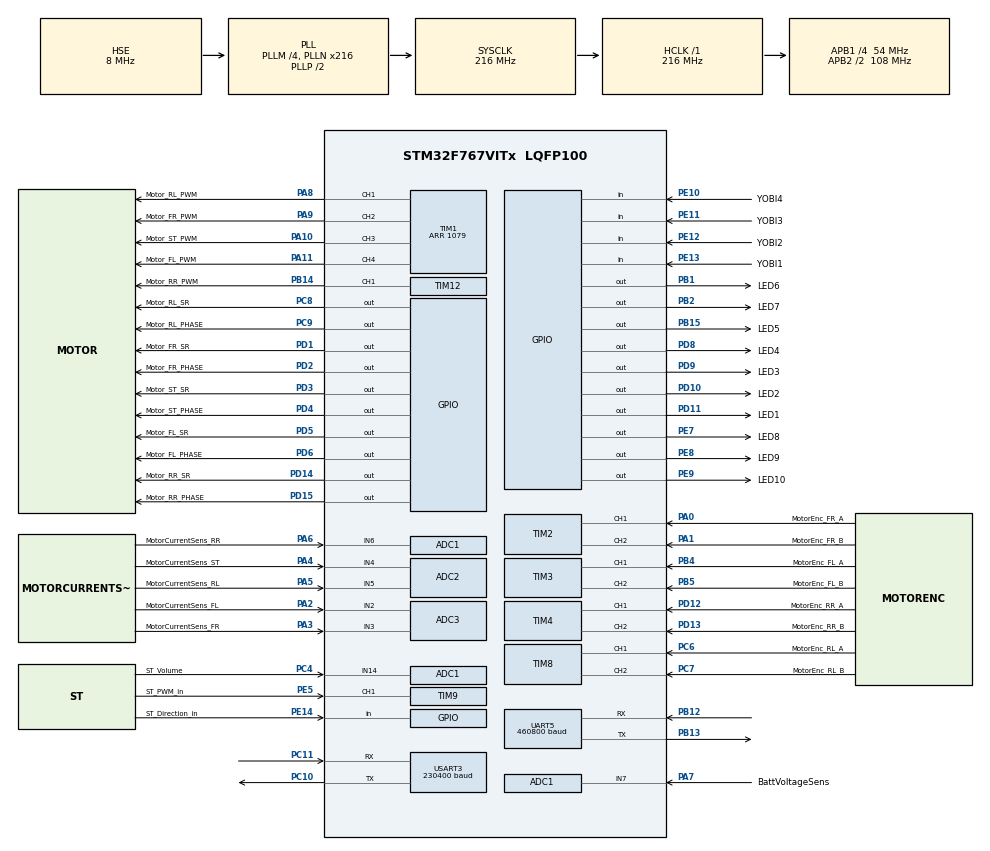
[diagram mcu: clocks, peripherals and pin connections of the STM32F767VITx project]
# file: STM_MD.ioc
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ADC1.Channel-1\#ChannelRegularConversion=ADC_CHANNEL_7
ADC1.Channel-2\#ChannelRegularConversion=ADC_CHANNEL_14
ADC1.Channel-3\#ChannelInjectedConversion=ADC_CHANNEL_6
ADC1.ContinuousConvMode=ENABLE
ADC1.DMAContinuousRequests=ENABLE
ADC1.DiscontinuousConvMode=DISABLE
ADC1.EnableAnalogWatchDog=false
ADC1.ExternalTrigInjecConv=ADC_EXTERNALTRIGINJECCONV_T1_TRGO
ADC1.InjNumberOfConversion=1
ADC1.InjectedOffset-3\#ChannelInjectedConversion=0
ADC1.InjectedRank-3\#ChannelInjectedConversion=1
ADC1.NbrOfConversion=2
ADC1.NbrOfConversionFlag=1
ADC1.Rank-1\#ChannelRegularConversion=1
ADC1.Rank-2\#ChannelRegularConversion=2
ADC1.SamplingTime-1\#ChannelRegularConversion=ADC_SAMPLETIME_3CYCLES
ADC1.SamplingTime-2\#ChannelRegularConversion=ADC_SAMPLETIME_3CYCLES
ADC1.SamplingTime-3\#ChannelInjectedConversion=ADC_SAMPLETIME_480CYCLES
ADC1.ScanConvMode=ADC_SCAN_ENABLE
ADC1.master=1
ADC2.Channel-0\#ChannelRegularConversion=ADC_CHANNEL_4
ADC2.Channel-3\#ChannelInjectedConversion=ADC_CHANNEL_4
ADC2.Channel-4\#ChannelInjectedConversion=ADC_CHANNEL_5
ADC2.ContinuousConvMode=ENABLE
ADC2.DMAContinuousRequests=ENABLE
ADC2.ExternalTrigInjecConv=ADC_EXTERNALTRIGINJECCONV_T1_TRGO
ADC2.InjNumberOfConversion=2
ADC2.InjectedOffset-3\#ChannelInjectedConversion=0
ADC2.InjectedOffset-4\#ChannelInjectedConversion=0
ADC2.InjectedRank-3\#ChannelInjectedConversion=1
ADC2.InjectedRank-4\#ChannelInjectedConversion=2
ADC2.NbrOfConversion=1
ADC2.NbrOfConversionFlag=1
ADC2.Rank-0\#ChannelRegularConversion=1
ADC2.SamplingTime-0\#ChannelRegularConversion=ADC_SAMPLETIME_84CYCLES
ADC2.SamplingTime-3\#ChannelInjectedConversion=ADC_SAMPLETIME_3CYCLES
ADC2.SamplingTime-4\#ChannelInjectedConversion=ADC_SAMPLETIME_3CYCLES
ADC2.ScanConvMode=ADC_SCAN_ENABLE
ADC3.Channel-0\#ChannelRegularConversion=ADC_CHANNEL_2
ADC3.Channel-1\#ChannelRegularConversion=ADC_CHANNEL_3
ADC3.Channel-2\#ChannelInjectedConversion=ADC_CHANNEL_2
ADC3.Channel-3\#ChannelInjectedConversion=ADC_CHANNEL_3
ADC3.ClockPrescaler=ADC_CLOCK_SYNC_PCLK_DIV4
ADC3.ContinuousConvMode=ENABLE
ADC3.DMAContinuousRequests=ENABLE
ADC3.ExternalTrigInjecConv=ADC_EXTERNALTRIGINJECCONV_T1_TRGO
ADC3.InjNumberOfConversion=2
ADC3.InjectedOffset-2\#ChannelInjectedConversion=0
ADC3.InjectedOffset-3\#ChannelInjectedConversion=0
ADC3.InjectedRank-2\#ChannelInjectedConversion=1
ADC3.InjectedRank-3\#ChannelInjectedConversion=2
ADC3.NbrOfConversion=2
ADC3.NbrOfConversionFlag=1
ADC3.Rank-0\#ChannelRegularConversion=1
ADC3.Rank-1\#ChannelRegularConversion=2
ADC3.SamplingTime-0\#ChannelRegularConversion=ADC_SAMPLETIME_112CYCLES
ADC3.SamplingTime-1\#ChannelRegularConversion=ADC_SAMPLETIME_112CYCLES
ADC3.SamplingTime-2\#ChannelInjectedConversion=ADC_SAMPLETIME_3CYCLES
ADC3.SamplingTime-3\#ChannelInjectedConversion=ADC_SAMPLETIME_3CYCLES
ADC3.ScanConvMode=ADC_SCAN_ENABLE
CORTEX_M7.ART_ACCELERATOR_ENABLE=1
CORTEX_M7.CPU_DCache=Enabled
CORTEX_M7.CPU_ICache=Enabled
CORTEX_M7.FlashInterface=TCM_Enabled
CORTEX_M7.PREFETCH_ENABLE=1
CORTEX_M7.default_mode_Activation=0
Dma.ADC1.0.Direction=DMA_PERIPH_TO_MEMORY
Dma.ADC1.0.FIFOMode=DMA_FIFOMODE_DISABLE
Dma.ADC1.0.Instance=DMA2_Stream0
Dma.ADC1.0.MemDataAlignment=DMA_MDATAALIGN_HALFWORD
Dma.ADC1.0.MemInc=DMA_MINC_ENABLE
Dma.ADC1.0.Mode=DMA_CIRCULAR
Dma.ADC1.0.PeriphDataAlignment=DMA_PDATAALIGN_HALFWORD
Dma.ADC1.0.PeriphInc=DMA_PINC_DISABLE
Dma.ADC1.0.Priority=DMA_PRIORITY_LOW
Dma.ADC2.3.Direction=DMA_PERIPH_TO_MEMORY
Dma.ADC2.3.FIFOMode=DMA_FIFOMODE_DISABLE
Dma.ADC2.3.Instance=DMA2_Stream2
Dma.ADC2.3.MemDataAlignment=DMA_MDATAALIGN_HALFWORD
Dma.ADC2.3.MemInc=DMA_MINC_ENABLE
Dma.ADC2.3.Mode=DMA_CIRCULAR
Dma.ADC2.3.PeriphDataAlignment=DMA_PDATAALIGN_HALFWORD
Dma.ADC2.3.PeriphInc=DMA_PINC_DISABLE
Dma.ADC2.3.Priority=DMA_PRIORITY_LOW
Dma.ADC3.4.Direction=DMA_PERIPH_TO_MEMORY
Dma.ADC3.4.FIFOMode=DMA_FIFOMODE_DISABLE
Dma.ADC3.4.Instance=DMA2_Stream1
Dma.ADC3.4.MemDataAlignment=DMA_MDATAALIGN_HALFWORD
Dma.ADC3.4.MemInc=DMA_MINC_ENABLE
Dma.ADC3.4.Mode=DMA_CIRCULAR
Dma.ADC3.4.PeriphDataAlignment=DMA_PDATAALIGN_HALFWORD
Dma.ADC3.4.PeriphInc=DMA_PINC_DISABLE
Dma.ADC3.4.Priority=DMA_PRIORITY_LOW
Dma.Request0=ADC1
Dma.Request1=UART5_RX
Dma.Request2=UART5_TX
Dma.Request3=ADC2
Dma.Request4=ADC3
Dma.UART5_RX.1.Direction=DMA_PERIPH_TO_MEMORY
Dma.UART5_RX.1.FIFOMode=DMA_FIFOMODE_DISABLE
Dma.UART5_RX.1.Instance=DMA1_Stream0
Dma.UART5_RX.1.MemDataAlignment=DMA_MDATAALIGN_BYTE
Dma.UART5_RX.1.MemInc=DMA_MINC_ENABLE
Dma.UART5_RX.1.Mode=DMA_CIRCULAR
Dma.UART5_RX.1.PeriphDataAlignment=DMA_PDATAALIGN_BYTE
Dma.UART5_RX.1.PeriphInc=DMA_PINC_DISABLE
Dma.UART5_RX.1.Priority=DMA_PRIORITY_LOW
Dma.UART5_TX.2.Direction=DMA_MEMORY_TO_PERIPH
Dma.UART5_TX.2.FIFOMode=DMA_FIFOMODE_DISABLE
Dma.UART5_TX.2.Instance=DMA1_Stream7
Dma.UART5_TX.2.MemDataAlignment=DMA_MDATAALIGN_BYTE
Dma.UART5_TX.2.MemInc=DMA_MINC_ENABLE
Dma.UART5_TX.2.Mode=DMA_NORMAL
Dma.UART5_TX.2.PeriphDataAlignment=DMA_PDATAALIGN_BYTE
Dma.UART5_TX.2.PeriphInc=DMA_PINC_DISABLE
Dma.UART5_TX.2.Priority=DMA_PRIORITY_LOW
IWDG.Prescaler=IWDG_PRESCALER_32
IWDG.Reload=4000
IWDG.Window=4000
Mcu.Family=STM32F7
Mcu.Name=STM32F767VITx
Mcu.Package=LQFP100
NVIC.DMA1_Stream0_IRQn=true\:0\:0\:false\:false\:true\:false\:true\:true
NVIC.DMA1_Stream7_IRQn=true\:0\:0\:false\:false\:true\:false\:true\:true
NVIC.DMA2_Stream0_IRQn=true\:0\:0\:false\:false\:true\:false\:true\:true
NVIC.DMA2_Stream1_IRQn=true\:0\:0\:false\:false\:true\:false\:true\:true
NVIC.DMA2_Stream2_IRQn=true\:0\:0\:false\:false\:true\:false\:true\:true
NVIC.PriorityGroup=NVIC_PRIORITYGROUP_4
NVIC.TIM1_BRK_TIM9_IRQn=true\:0\:0\:false\:false\:true\:true\:true\:true
NVIC.TIM8_TRG_COM_TIM14_IRQn=true\:0\:0\:false\:false\:true\:true\:true\:true
NVIC.UART5_IRQn=true\:0\:0\:false\:false\:true\:true\:true\:true
PA0/WKUP.GPIO_Label=MotorEnc_FR_A
PA0/WKUP.Signal=S_TIM2_CH1_ETR
PA1.GPIO_Label=MotorEnc_FR_B
PA1.Signal=S_TIM2_CH2
PA10.GPIO_Label=Motor_ST_PWM
PA10.Signal=S_TIM1_CH3
PA11.GPIO_Label=Motor_FL_PWM
PA11.Signal=S_TIM1_CH4
PA13.Mode=Trace_Asynchronous_SW
PA13.Signal=SYS_JTMS-SWDIO
PA14.Mode=Trace_Asynchronous_SW
PA14.Signal=SYS_JTCK-SWCLK
PA2.GPIO_Label=MotorCurrentSens_FL
PA2.Signal=ADCx_IN2
PA3.GPIO_Label=MotorCurrentSens_FR
PA3.Signal=ADCx_IN3
PA4.GPIO_Label=MotorCurrentSens_ST
PA4.Signal=ADCx_IN4
PA5.GPIO_Label=MotorCurrentSens_RL
PA5.Signal=ADCx_IN5
PA6.GPIO_Label=MotorCurrentSens_RR
PA6.Signal=ADCx_IN6
PA7.GPIO_Label=BattVoltageSens
PA7.Signal=ADCx_IN7
PA8.GPIO_Label=Motor_RL_PWM
PA8.Signal=S_TIM1_CH1
PA9.GPIO_Label=Motor_FR_PWM
PA9.Signal=S_TIM1_CH2
PB1.GPIO_Label=LED6
PB1.Signal=GPIO_Output
PB12.GPIO_PuPd=GPIO_NOPULL
PB12.Mode=Asynchronous
PB12.Signal=UART5_RX
PB13.Mode=Asynchronous
PB13.Signal=UART5_TX
PB14.GPIO_Label=Motor_RR_PWM
PB14.Signal=S_TIM12_CH1
PB15.GPIO_Label=LED5
PB15.Signal=GPIO_Output
PB2.GPIO_Label=LED7
PB2.Signal=GPIO_Output
PB3.Mode=Trace_Asynchronous_SW
PB3.Signal=SYS_JTDO-SWO
PB4.GPIO_Label=MotorEnc_FL_A
PB4.Signal=S_TIM3_CH1
PB5.GPIO_Label=MotorEnc_FL_B
PB5.Signal=S_TIM3_CH2
PC10.Mode=Asynchronous
PC10.Signal=USART3_TX
PC11.Mode=Asynchronous
PC11.Signal=USART3_RX
PC4.GPIO_Label=ST_Volume
PC4.Signal=ADCx_IN14
PC6.GPIO_Label=MotorEnc_RL_A
PC6.Signal=S_TIM8_CH1
PC7.GPIO_Label=MotorEnc_RL_B
PC7.Signal=S_TIM8_CH2
PC8.GPIO_Label=Motor_RL_SR
PC8.Signal=GPIO_Output
PC9.GPIO_Label=Motor_RL_PHASE
PC9.Signal=GPIO_Output
PD1.GPIO_Label=Motor_FR_SR
PD1.Signal=GPIO_Output
PD10.GPIO_Label=LED2
PD10.Signal=GPIO_Output
PD11.GPIO_Label=LED1
PD11.Signal=GPIO_Output
PD12.GPIO_Label=MotorEnc_RR_A
PD12.Signal=S_TIM4_CH1
PD13.GPIO_Label=MotorEnc_RR_B
PD13.Signal=S_TIM4_CH2
PD14.GPIO_Label=Motor_RR_SR
PD14.Signal=GPIO_Output
PD15.GPIO_Label=Motor_RR_PHASE
PD15.Signal=GPIO_Output
PD2.GPIO_Label=Motor_FR_PHASE
PD2.Signal=GPIO_Output
PD3.GPIO_Label=Motor_ST_SR
PD3.Signal=GPIO_Output
PD4.GPIO_Label=Motor_ST_PHASE
PD4.Signal=GPIO_Output
PD5.GPIO_Label=Motor_FL_SR
PD5.Signal=GPIO_Output
PD6.GPIO_Label=Motor_FL_PHASE
PD6.Signal=GPIO_Output
PD8.GPIO_Label=LED4
PD8.Signal=GPIO_Output
PD9.GPIO_Label=LED3
PD9.Signal=GPIO_Output
PE10.GPIO_Label=YOBI4
PE10.Signal=GPIO_Input
PE11.GPIO_Label=YOBI3
PE11.Signal=GPIO_Input
PE12.GPIO_Label=YOBI2
PE12.Signal=GPIO_Input
PE13.GPIO_Label=YOBI1
PE13.Signal=GPIO_Input
PE14.GPIO_Label=ST_Direction_in
PE14.Signal=GPIO_Input
PE5.GPIO_Label=ST_PWM_in
PE5.Signal=S_TIM9_CH1
PE7.GPIO_Label=LED8
PE7.Signal=GPIO_Output
PE8.GPIO_Label=LED9
PE8.Signal=GPIO_Output
PE9.GPIO_Label=LED10
PE9.Signal=GPIO_Output
PH0/OSC_IN.Mode=HSE-External-Clock-Source
PH0/OSC_IN.Signal=RCC_OSC_IN
PH1/OSC_OUT.Mode=HSE-External-Clock-Source
PH1/OSC_OUT.Signal=RCC_OSC_OUT
ProjectManager.HeapSize=0x200
ProjectManager.StackSize=0x400
ProjectManager.TargetToolchain=CMake
RCC.AHBFreq_Value=216000000
RCC.APB1CLKDivider=RCC_HCLK_DIV4
RCC.APB1Freq_Value=54000000
RCC.APB1TimFreq_Value=108000000
RCC.APB2CLKDivider=RCC_HCLK_DIV2
RCC.APB2Freq_Value=108000000
RCC.APB2TimFreq_Value=216000000
RCC.CortexFreq_Value=216000000
RCC.HCLKFreq_Value=216000000
RCC.HSE_VALUE=8000000
RCC.HSI_VALUE=16000000
RCC.LSE_VALUE=32768
RCC.PLLM=4
RCC.PLLN=216
RCC.PLLQ=9
RCC.PLLSourceVirtual=RCC_PLLSOURCE_HSE
RCC.SYSCLKFreq_VALUE=216000000
RCC.SYSCLKSource=RCC_SYSCLKSOURCE_PLLCLK
RCC.USBFreq_Value=48000000
RCC.VCOOutputFreq_Value=432000000
SH.ADCx_IN14.0=ADC1_IN14,IN14
SH.ADCx_IN2.0=ADC3_IN2,IN2
SH.ADCx_IN3.0=ADC3_IN3,IN3
SH.ADCx_IN4.0=ADC2_IN4,IN4
SH.ADCx_IN5.0=ADC2_IN5,IN5
SH.ADCx_IN6.0=ADC1_IN6,IN6
SH.ADCx_IN7.0=ADC1_IN7,IN7
SH.S_TIM12_CH1.0=TIM12_CH1,PWM Generation1 CH1
SH.S_TIM1_CH1.0=TIM1_CH1,PWM Generation1 CH1
SH.S_TIM1_CH2.0=TIM1_CH2,PWM Generation2 CH2
SH.S_TIM1_CH3.0=TIM1_CH3,PWM Generation3 CH3
SH.S_TIM1_CH4.0=TIM1_CH4,PWM Generation4 CH4
SH.S_TIM2_CH1_ETR.0=TIM2_CH1,Encoder_Interface
SH.S_TIM2_CH2.0=TIM2_CH2,Encoder_Interface
SH.S_TIM3_CH1.0=TIM3_CH1,Encoder_Interface
SH.S_TIM3_CH2.0=TIM3_CH2,Encoder_Interface
SH.S_TIM4_CH1.0=TIM4_CH1,Encoder_Interface
SH.S_TIM4_CH2.0=TIM4_CH2,Encoder_Interface
SH.S_TIM8_CH1.0=TIM8_CH1,Encoder_Interface
SH.S_TIM8_CH2.0=TIM8_CH2,Encoder_Interface
SH.S_TIM9_CH1.0=TIM9_CH1,PWM_Input_1
TIM1.AutoReloadPreload=TIM_AUTORELOAD_PRELOAD_ENABLE
TIM1.Channel-PWM\ Generation1\ CH1=TIM_CHANNEL_1
TIM1.Channel-PWM\ Generation2\ CH2=TIM_CHANNEL_2
TIM1.Channel-PWM\ Generation3\ CH3=TIM_CHANNEL_3
TIM1.Channel-PWM\ Generation4\ CH4=TIM_CHANNEL_4
TIM1.CounterMode=TIM_COUNTERMODE_CENTERALIGNED2
TIM1.Period=1079
TIM1.TIM_MasterOutputTrigger=TIM_TRGO_UPDATE
TIM1.TIM_MasterSlaveMode=TIM_MASTERSLAVEMODE_ENABLE
TIM12.AutoReloadPreload=TIM_AUTORELOAD_PRELOAD_ENABLE
TIM12.Channel-PWM\ Generation1\ CH1=TIM_CHANNEL_1
TIM12.Period=1079
TIM14.Period=5399
TIM2.EncoderMode=TIM_ENCODERMODE_TI12
TIM3.EncoderMode=TIM_ENCODERMODE_TI12
TIM4.EncoderMode=TIM_ENCODERMODE_TI12
TIM5.Channel-PWM\ Generation1\ No\ Output=TIM_CHANNEL_1
TIM5.Period=1000
TIM5.TIM_MasterOutputTrigger=TIM_TRGO_UPDATE
TIM5.TIM_MasterSlaveMode=TIM_MASTERSLAVEMODE_ENABLE
TIM8.EncoderMode=TIM_ENCODERMODE_TI12
UART5.BaudRate=460800
USART3.BaudRate=230400
USART3.VirtualMode-Asynchronous=VM_ASYNC
VP_CRC_VS_CRC.Mode=CRC_Activate
VP_IWDG_VS_IWDG.Mode=IWDG_Activate
VP_TIM12_VS_ClockSourceITR.Mode=TriggerSource_ITR1
VP_TIM12_VS_ControllerModeTrigger.Mode=Trigger Mode
VP_TIM14_VS_ClockSourceINT.Mode=Enable_Timer
VP_TIM1_VS_ClockSourceITR.Mode=TriggerSource_ITR0
VP_TIM1_VS_ControllerModeTrigger.Mode=Trigger Mode
VP_TIM5_VS_no_output1.Mode=PWM Generation1 No Output
VP_TIM6_VS_ClockSourceINT.Mode=Enable_Timer
board=custom

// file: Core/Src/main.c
/* USER CODE BEGIN Header */
/**
 ******************************************************************************
 * @file           : main.c
 * @brief          : Main program body
 ******************************************************************************
 * @attention
 *
 * Copyright (c) 2023 STMicroelectronics.
 * All rights reserved.
 *
 * This software is licensed under terms that can be found in the LICENSE file
 * in the root directory of this software component.
 * If no LICENSE file comes with this software, it is provided AS-IS.
 *
 ******************************************************************************
 */
/* USER CODE END Header */
#include "main.h"
#include "adc.h"
#include "crc.h"
#include "dma.h"
#include "iwdg.h"
#include "tim.h"
#include "usart.h"
#include "gpio.h"

/* USER CODE BEGIN Includes */
#include "app_main.h"
/* USER CODE END Includes */

void SystemClock_Config(void);

/* USER CODE BEGIN 0 */
#ifdef __GNUC__
#define PUTCHAR_PROTOTYPE int __io_putchar(int ch)
#else
#define PUTCHAR_PROTOTYPE int fputc(int ch, FILE* f)
#endif /*__GNUC__*/
/* USER CODE END 0 */

int main(void)
{

  /* Enable the CPU Cache */

  /* Enable I-Cache---------------------------------------------------------*/
  SCB_EnableICache();

  /* Enable D-Cache---------------------------------------------------------*/
  SCB_EnableDCache();

  /* MCU Configuration--------------------------------------------------------*/

  /* Reset of all peripherals, Initializes the Flash interface and the Systick. */
  HAL_Init();

  /* Configure the system clock */
  SystemClock_Config();

  /* Initialize all configured peripherals */
  MX_GPIO_Init();
  MX_DMA_Init();
  MX_TIM2_Init();
  MX_TIM3_Init();
  MX_TIM4_Init();
  MX_TIM8_Init();
  MX_ADC1_Init();
  MX_TIM1_Init();
  MX_TIM12_Init();
  MX_UART5_Init();
  MX_TIM9_Init();
  MX_CRC_Init();
  MX_USART3_UART_Init();
  MX_TIM14_Init();
  MX_ADC2_Init();
  MX_ADC3_Init();
  MX_TIM5_Init();
  MX_IWDG_Init();
  MX_TIM6_Init();

  /* Infinite loop */
  /* USER CODE BEGIN WHILE */
    while (1) {
        app_main();
    /* USER CODE END WHILE */

    }
}

void SystemClock_Config(void)
{
  RCC_OscInitTypeDef RCC_OscInitStruct = {0};
  RCC_ClkInitTypeDef RCC_ClkInitStruct = {0};

  /** Configure the main internal regulator output voltage
  */
  __HAL_RCC_PWR_CLK_ENABLE();
  __HAL_PWR_VOLTAGESCALING_CONFIG(PWR_REGULATOR_VOLTAGE_SCALE1);

  /** Initializes the RCC Oscillators according to the specified parameters
  * in the RCC_OscInitTypeDef structure.
  */
  RCC_OscInitStruct.OscillatorType = RCC_OSCILLATORTYPE_LSI|RCC_OSCILLATORTYPE_HSE;
  RCC_OscInitStruct.HSEState = RCC_HSE_BYPASS;
  RCC_OscInitStruct.LSIState = RCC_LSI_ON;
  RCC_OscInitStruct.PLL.PLLState = RCC_PLL_ON;
  RCC_OscInitStruct.PLL.PLLSource = RCC_PLLSOURCE_HSE;
  RCC_OscInitStruct.PLL.PLLM = 4;
  RCC_OscInitStruct.PLL.PLLN = 216;
  RCC_OscInitStruct.PLL.PLLP = RCC_PLLP_DIV2;
  RCC_OscInitStruct.PLL.PLLQ = 9;
  RCC_OscInitStruct.PLL.PLLR = 2;
  if (HAL_RCC_OscConfig(&RCC_OscInitStruct) != HAL_OK)
  {
    Error_Handler();
  }

  /** Activate the Over-Drive mode
  */
  if (HAL_PWREx_EnableOverDrive() != HAL_OK)
  {
    Error_Handler();
  }

  /** Initializes the CPU, AHB and APB buses clocks
  */
  RCC_ClkInitStruct.ClockType = RCC_CLOCKTYPE_HCLK|RCC_CLOCKTYPE_SYSCLK
                              |RCC_CLOCKTYPE_PCLK1|RCC_CLOCKTYPE_PCLK2;
  RCC_ClkInitStruct.SYSCLKSource = RCC_SYSCLKSOURCE_PLLCLK;
  RCC_ClkInitStruct.AHBCLKDivider = RCC_SYSCLK_DIV1;
  RCC_ClkInitStruct.APB1CLKDivider = RCC_HCLK_DIV4;
  RCC_ClkInitStruct.APB2CLKDivider = RCC_HCLK_DIV2;

  if (HAL_RCC_ClockConfig(&RCC_ClkInitStruct, FLASH_LATENCY_7) != HAL_OK)
  {
    Error_Handler();
  }
}

/* USER CODE BEGIN 4 */
PUTCHAR_PROTOTYPE {
    HAL_UART_Transmit(&huart3, (uint8_t*)&ch, 1, 0xFFFF);
    return ch;
}
/* USER CODE END 4 */

void Error_Handler(void)
{
    __disable_irq();
    while (1) {
    }
}
